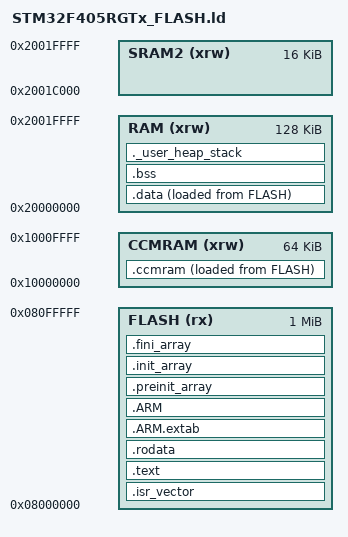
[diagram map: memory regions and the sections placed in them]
/*
 * STM32F405RGTx_FLASH.ld — Linker script for STM32F405RGT6
 *
 * Memory map:
 *   FLASH:  0x08000000 — 1 MB  (program code + const data)
 *   SRAM1:  0x20000000 — 128 KB (main RAM: stack, BSS, data)
 *   SRAM2:  0x2001C000 — 16 KB  (can be used for NN weights if needed)
 *   CCMRAM: 0x10000000 — 64 KB  (Core Coupled Memory — CPU access only)
 *
 * Usage notes:
 *   - Stack grows downward from _estack (top of SRAM1)
 *   - Heap is unused (no malloc) — _end marks BSS end
 *   - Large NN weight array (~32 KB) fits in SRAM1 comfortably
 *   - To place NN_Handle_t in CCMRAM for zero-wait access:
 *       __attribute__((section(".ccmram"))) static NN_Handle_t s_nn;
 *
 * This file is typically auto-generated by STM32CubeMX.
 * It is included here for terminal build completeness.
 */

ENTRY(Reset_Handler)

_estack = ORIGIN(RAM) + LENGTH(RAM);   /* Top of SRAM1 = initial stack pointer */

_Min_Heap_Size  = 0x0;    /* No dynamic heap needed */
_Min_Stack_Size = 0x800;  /* 2 KB minimum stack reserve */

MEMORY
{
  CCMRAM  (xrw) : ORIGIN = 0x10000000, LENGTH = 64K
  FLASH   (rx)  : ORIGIN = 0x08000000, LENGTH = 1024K
  RAM     (xrw) : ORIGIN = 0x20000000, LENGTH = 128K
  SRAM2   (xrw) : ORIGIN = 0x2001C000, LENGTH = 16K
}

SECTIONS
{
  /* Interrupt vector table — must be at start of flash */
  .isr_vector :
  {
    . = ALIGN(4);
    KEEP(*(.isr_vector))
    . = ALIGN(4);
  } >FLASH

  /* Program code and read-only data */
  .text :
  {
    . = ALIGN(4);
    *(.text)
    *(.text*)
    *(.glue_7)
    *(.glue_7t)
    *(.eh_frame)
    KEEP(*(.init))
    KEEP(*(.fini))
    . = ALIGN(4);
    _etext = .;
  } >FLASH

  /* Constants in flash */
  .rodata :
  {
    . = ALIGN(4);
    *(.rodata)
    *(.rodata*)
    . = ALIGN(4);
  } >FLASH

  /* ARM exception unwind tables */
  .ARM.extab : { *(.ARM.extab* .gnu.linkonce.armextab.*) } >FLASH
  .ARM        : {
    __exidx_start = .;
    *(.ARM.exidx*)
    __exidx_end = .;
  } >FLASH

  /* Pre-init and init arrays */
  .preinit_array :
  {
    PROVIDE_HIDDEN(__preinit_array_start = .);
    KEEP(*(.preinit_array*))
    PROVIDE_HIDDEN(__preinit_array_end = .);
  } >FLASH

  .init_array :
  {
    PROVIDE_HIDDEN(__init_array_start = .);
    KEEP(*(SORT(.init_array.*)))
    KEEP(*(.init_array*))
    PROVIDE_HIDDEN(__init_array_end = .);
  } >FLASH

  .fini_array :
  {
    PROVIDE_HIDDEN(__fini_array_start = .);
    KEEP(*(SORT(.fini_array.*)))
    KEEP(*(.fini_array*))
    PROVIDE_HIDDEN(__fini_array_end = .);
  } >FLASH

  /* Initialized data — loaded from flash, copied to RAM at startup */
  _sidata = LOADADDR(.data);
  .data :
  {
    . = ALIGN(4);
    _sdata = .;
    *(.data)
    *(.data*)
    . = ALIGN(4);
    _edata = .;
  } >RAM AT> FLASH

  /* CCM section — for performance-critical data (e.g., NN weights) */
  _siccmram = LOADADDR(.ccmram);
  .ccmram :
  {
    . = ALIGN(4);
    _sccmram = .;
    *(.ccmram)
    *(.ccmram*)
    . = ALIGN(4);
    _eccmram = .;
  } >CCMRAM AT> FLASH

  /* Zero-initialized data (BSS) — zeroed by startup code */
  .bss :
  {
    . = ALIGN(4);
    _sbss = .;
    *(.bss)
    *(.bss*)
    *(COMMON)
    . = ALIGN(4);
    _ebss = .;
  } >RAM

  /* Symbol exported for Utils_PrintMemoryStats() */
  _end = _ebss;

  /* Stack and heap guard — verifies minimum sizes fit in RAM */
  ._user_heap_stack :
  {
    . = ALIGN(8);
    PROVIDE(end = .);
    . = . + _Min_Heap_Size;
    . = . + _Min_Stack_Size;
    . = ALIGN(8);
  } >RAM

  /* Discard C++ exception and debug sections to save flash */
  /DISCARD/ :
  {
    libc.a(*)
    libm.a(*)
    libgcc.a(*)
  }

  .ARM.attributes 0 : { *(.ARM.attributes) }
}
